# SAM9X75D5M device description
Architecture: ARM926EJ-S; Family: SAM9; Series: SAM9X7
Registers are 32-bit, read-write, reset 0x0 unless marked. A register's access mark holds for its fields unless they carry their own. Offsets are from the block's base; [hi:lo] are bit positions; {n}, {i} and the like mark numbered series; 'fields as' and 'values as' point back to an identical list.

## GMAC (part 2 of 3) — Gigabit Ethernet MAC
Instances: GMAC 0xF802C000
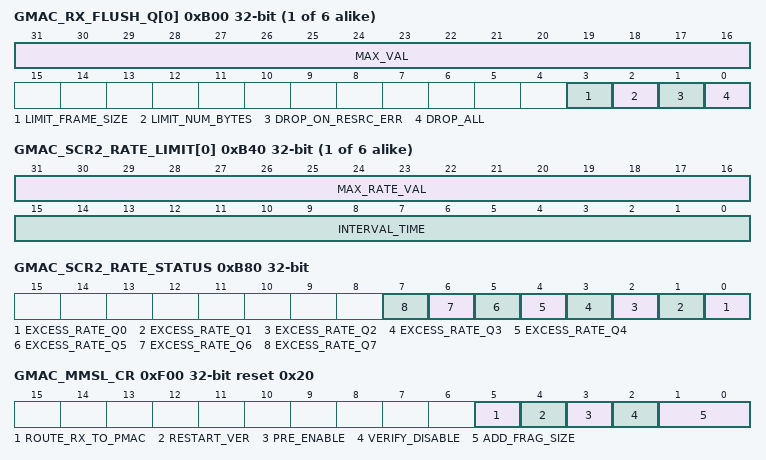
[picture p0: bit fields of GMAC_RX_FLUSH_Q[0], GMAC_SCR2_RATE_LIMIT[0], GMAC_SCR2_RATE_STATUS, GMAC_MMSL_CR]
{0xB00+4i} GMAC_RX_FLUSH_Q[{i}] (i=0..5) — Receive Queue Flush Register (index = 0)
  [31:16] MAX_VAL — Maximum Value for the Received Frame Size or Number of 128-Byte Chunk
  [3] LIMIT_FRAME_SIZE — Maximum Frame-length Received
    0=DISABLED (No effect.); 1=ENABLED (When set, MAX_VAL indicates the maximum frame-length in bytes that may be received. Frames exceeding this length will be dropped. This traffic policing function is relevant to the 802.1Qci standard which specifies stream filtering based on a maximum service data unit (SDU) size.)
  [2] LIMIT_NUM_BYTES — Limitation of the Number of 128-Byte Chunk of Data Stored in the Memory of this Queue
    0=DISABLED (No effect.); 1=ENABLED (Limits the number of 128 byte chunks of data received for this queue and already stored in the memory of the queue awaiting DMA memory writes to the value defined in the field MAX_VAL.)
  [1] DROP_ON_RESRC_ERR — Drop on Resource Error
    0=DISABLED (No effect.); 1=ENABLED (If a free DMA descriptor for this queue cannot be obtained (also referred to as lack of descriptor resource and occurs when the software either cannot free up descriptors quickly enough to meet the receive traffic rate or has deliberately decided not to free any descriptors), all new frames received on this queue will be automatically discarded.)
  [0] DROP_ALL — Drop All Frames
    0=DISABLED (No effect.); 1=ENABLED (Drops all frames of this queue.)
{0xB40+4i} GMAC_SCR2_RATE_LIMIT[{i}] (i=0..5) — Screening 2 Rate Limit Register (index = 0)
  [31:16] MAX_RATE_VAL — Maximum Rate Value for the Interval Time
  [15:0] INTERVAL_TIME — Interval Time for Maximum Rate Checking
0xB80 GMAC_SCR2_RATE_STATUS ro — Screening 2 Rate Status Register
  [all] fields
    0=No excessive rate in screener since the last read of GMAC_SCR2_RATE_STATUS; 1=A screener rate limiting mechanism has been triggered since the last read of GMAC_SCR2_RATE_STATUS
  [n] EXCESS_RATE_Q{n} (n=0..7) — Excessive Screener Rate Queue {n}
0xF00 GMAC_MMSL_CR reset 0x20 — MMSL Control Register
  [5] ROUTE_RX_TO_PMAC — Route Received Frames to Preemptive MAC
    0=Routes all received to express MAC (eMAC); 1=Routes all received frames to preemptive MAC (pMAC)
  [4] RESTART_VER — Restart the Verification Procedure (Write-only)
    0=No effect; 1=Restarts the verification procedure. Writing a one to this bit has no effect if any of the following are true: PRE_ENABLE=0, VERIFY_DISABLE=1 or the verification procedure is already in progress. When preemption is active, ROUTE_RX_TO_PMAC must be set to zero before writing to the RESTART_VER bit. This bit always returns zero when read.
  [3] PRE_ENABLE — Preemption Operation Enable
    0=Disables the preemption operation and verify mpackets will not be responded to or sent. If a preemption is in progress, the current preemption will complete and no more preemption will occur.; 1=Enables the preemption by starting the verification procedure when VERIFY_DISABLE=0. Preemption can occur only once the verification process completes. If VERIFY_DISABLE=1, preemption can occur immediately.
  [2] VERIFY_DISABLE — 802.3br Support Check for the Link Partner
    0=Enables the 802.3br support check for the link partner; 1=Disables the 802.3br support check for the link partner and preemption is enabled as soon as PRE_ENABLE=1
  [1:0] ADD_FRAG_SIZE — PMAC Minimum Number of Bytes before Preemption
    0=64_BYTES (A minimum of 64 bytes can be sent by pMAC before any preemption. The value can be changed only when PRE_ENABLE is cleared); 1=128_BYTES (A minimum of 128 bytes can be sent by pMAC before any preemption. The value can be changed only when PRE_ENABLE is cleared); 2=192_BYTES (A minimum of 192 bytes can be sent by pMAC before any preemption. The value can be changed only when PRE_ENABLE is cleared); 3=256_BYTES (A minimum of 256 bytes can be sent by pMAC before any preemption. The value can be changed only when PRE_ENABLE is cleared)
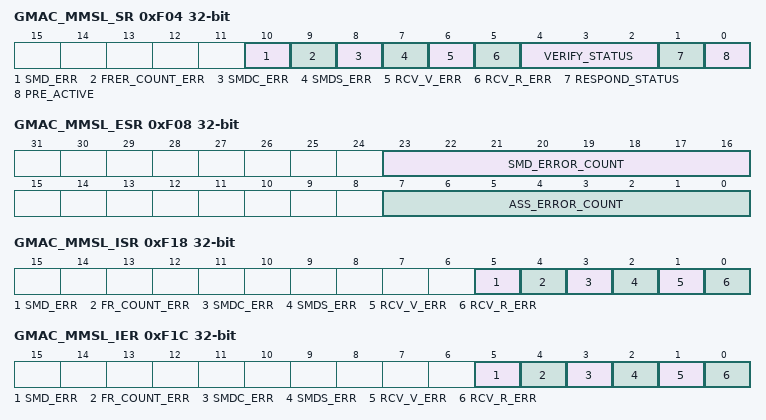
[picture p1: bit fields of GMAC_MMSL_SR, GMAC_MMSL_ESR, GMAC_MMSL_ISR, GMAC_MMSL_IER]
0xF04 GMAC_MMSL_SR ro — MMSL Status Register
  [10] SMD_ERR — Illegal Start Mpacket Delimiter Received (Clear on read)
    0=No error since the last read of GMAC_MMSL_SR; 1=An illegal SMD (different from Express, Verify, Response, Start Preemptible or Continuation Preemptible SMD) has been received since the last read of GMAC_MMSL_SR
  [9] FRER_COUNT_ERR — Frame Counter Error (Clear on read)
    0=No error since the last read of GMAC_MMSL_SR; 1=A frame counter error occurred since the last read of GMAC_MMSL_SR. A frame counter error occurs when the SMD-C received indicates a different frame count than expected (i.e. the fragment belongs to another frame and not to the Start packet already received before this) or when a fragment error happened, which means the field following the SMD-C received was encoding a different fragment count than it was supposed to be.
  [8] SMDC_ERR — SMD-C Received When Waiting an SMD-S (Clear on read)
    0=No error since the last read of GMAC_MMSL_SR; 1=An SMD-C has been received when an SMD-S was expected, since the last read of GMAC_MMSL_SR
  [7] SMDS_ERR — SMD-S Received When Waiting an SMD-C (Clear on read)
    0=No error since the last read of GMAC_MMSL_SR; 1=An SMD-S has been received when an SMD-C was expected, since the last read of GMAC_MMSL_SR
  [6] RCV_V_ERR — Incorrect Verification Mpacket Received (Clear on read)
    0=No error since the last read of GMAC_MMSL_SR; 1=An incorrect verification mPacket has been received since the last read of GMAC_MMSL_SR
  [5] RCV_R_ERR — Incorrect Response Mpacket Received (Clear on read)
    0=No error since the last read of GMAC_MMSL_SR; 1=An incorrect response mPacket has been received since the last read of GMAC_MMSL_SR
  [4:2] VERIFY_STATUS — Verification Status
    0=INIT_VERIFICATION (Initialization); 1=VERIFICATION_IDLE (Idle); 2=SEND_VERIFY (Sending a verify command); 3=WAIT_FOR_RESPONSE (Waiting for a response); 4=VERIFIED; 5=VERIFY_FAIL (Failure during the verify operation)
  [1] RESPOND_STATUS — Response Status
    0=R_IDLE (Idle); 1=SEND_RESPOND (Sending)
  [0] PRE_ACTIVE — Preemption Status
    0=Preemption is inactive; 1=Preemption is active when the verification process is completed or when GMAC_MMSL_CR.VERIFY_DISABLE=1 and GMAC_MMSL_CR.PRE_ACTIVE=1
0xF08 GMAC_MMSL_ESR ro — MMSL Error Statistics Register
  [23:16] SMD_ERROR_COUNT — Number of Rejected Frames or Fragments due to unknown SMD (Clear on read)
  [7:0] ASS_ERROR_COUNT — Number of Frames with Reassembly Errors (Clear on read)
0xF0C GMAC_MMSL_ASS_OK ro — MMSL Frame Re-Assembled OK Register
  [16:0] ASS_OK_COUNT — Number of Correctly Re-Assembled Frames (Clear on read)
0xF10 GMAC_MMSL_RXFRAG_CNT ro — MMSL Received Fragment Counter Register
  [16:0] FRAG_COUNT_RX — Number of Received Fragments (Clear on read)
0xF14 GMAC_MMSL_TXFRAG_CNT ro — MMSL Transmitted Fragment Counter Register
  [16:0] FRAG_COUNT_TX — Number of Transmitted Fragments (Clear on read)
0xF18 GMAC_MMSL_ISR — MMSL Interrupt Status Register
  [5] SMD_ERR — Illegal SMD Received (Clear on read)
    0=No illegal SMD received since the last read of GMAC_MMSL_ISR; 1=Illegal SMD received (different from Express, Verify, Response, Start Preemptible or Continuation Preemptible) since the last read of GMAC_MMSL_ISR
  [4] FR_COUNT_ERR — Illegal SMD Received (Clear on read)
    0=No frame count error detected since the last read of GMAC_MMSL_ISR; 1=The SMD-C received since the last read of GMAC_MMSL_ISR, indicates a different frame count than expected (i.e. the fragment belongs to another frame and not to the Start packet already received before this) or if a Fragment error happened, which means the field following the SMD-C received was encoding a different fragment count than it was supposed to be.
  [3] SMDC_ERR — SMD-C Received When Waiting an SMD-S (Clear on read)
    values as GMAC_MMSL_SR.SMDC_ERR
  [2] SMDS_ERR — SMD-S Received When Waiting an SMD-C (Clear on read)
    values as GMAC_MMSL_SR.SMDS_ERR
  [1] RCV_V_ERR — Incorrect Verification Mpacket Received (Clear on read)
    values as GMAC_MMSL_SR.RCV_V_ERR
  [0] RCV_R_ERR — Incorrect Response Mpacket Received (Clear on read)
    values as GMAC_MMSL_SR.RCV_R_ERR
0xF1C GMAC_MMSL_IER (atomic set of GMAC_MMSL_IMR) — MMSL Interrupt Enable Register
  [5] SMD_ERR — Illegal SMD Received
  [4] FR_COUNT_ERR — Illegal SMD Received
  [3] SMDC_ERR — SMD-C Received When Waiting an SMD-S
  [2] SMDS_ERR — SMD-S Received When Waiting an SMD-C
  [1] RCV_V_ERR — Incorrect Verification Mpacket Received
  [0] RCV_R_ERR — Incorrect Response Mpacket Received
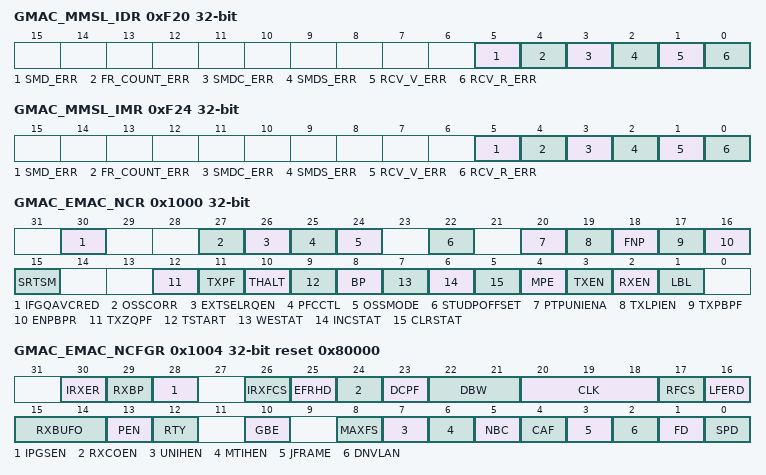
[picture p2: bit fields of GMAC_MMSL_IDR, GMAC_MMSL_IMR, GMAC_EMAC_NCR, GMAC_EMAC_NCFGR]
0xF20 GMAC_MMSL_IDR (atomic clear of GMAC_MMSL_IMR) — MMSL Interrupt Disable Register
  fields as GMAC_MMSL_IER
0xF24 GMAC_MMSL_IMR ro — MMSL Interrupt Mask Register
  fields as GMAC_MMSL_IER
0x1000 GMAC_EMAC_NCR — Express MAC Network Control Register
  [30] IFGQAVCRED — Credit-Based Shaping Algorithm Modification
    0=No modification of the CBS algorithm; 1=Modifies the CBS algorithm so the IFG/IPG associated with a transmit frame counts towards its 802.1Qav credit
  [27] OSSCORR — 1588 One Step Sync Mode Correction Field
    0=Disables updating the correction field of PTP 1588 version 2 sync frames by adding current TSU timer value; 1=Enables updating the correction field of PTP 1588 version 2 sync frames by adding current TSU timer value
  [26] EXTSELRQEN — External Selection of Receive Queue Enable
    0=Disables external selection of receive queue; 1=Enables external selection of receive queue
  [25] PFCCTL — Multiple PFC Pause quantum Enable
    0=Disables multiple PFC pause quantums; 1=Enables multiple PFC pause quantums, one per pause priority
  [24] OSSMODE — One Step Sync Mode
    0=1588 One Step Sync Mode is disabled; 1=1588 One Step Sync Mode is enabled. Replaces timestamp field in the 1588 header for TX Sync Frames with the current TSU timer value.
  [22] STUDPOFFSET — Store UDP Offset
    0=Normal operations; 1=The upper 16 bits of the CRC of every received frame are replaced with the offset from start of frame to the beginning of the UDP or TCP header. The lower 16 bits of the CRC are replaced with zero and reserved for future use. The offset is measured in units of 2 bytes.
  [20] PTPUNIENA — Detection of Unicast PTP Frames Enable
    0=Disables detection of unicast PTP frames; 1=Enables detection of unicast PTP frames
  [19] TXLPIEN — Enable LPI Transmission
  [18] FNP — Flush Next Packet (Write-only)
    0=No effect; 1=Flushes the next packet from the receive memory. This will only have an effect if the DMA is not currently writing a packet already stored in the receive memory to system memory.
  [17] TXPBPF — Transmit PFC Priority-based Pause Frame (Write-only)
    0=No effect; 1=Takes the values stored in the Transmit PFC Pause Register
  [16] ENPBPR — Enable PFC Priority-based Pause Reception
    0=Disables PFC Priority Based Pause Reception capabilities; 1=Enables PFC Priority Based Pause Reception capabilities by enabling the PFC negotiation and recognition of priority-based pause frames
  [15] SRTSM — Store Receive Timestamp to Memory
    0=Normal operation; 1=Causes the CRC of every received frame to be replaced with the value of the nanoseconds field of the 1588 timer that was captured as the receive frame passed the message timestamp point. Note that bit RFCS in register GMAC_NCFGR may not be set to 1 when the timer should be captured.
  [12] TXZQPF — Transmit Zero Quantum Pause Frame (Write-only)
    0=No effect; 1=Generates a pause frame with zero quantum to be transmitted
  [11] TXPF — Transmit Pause Frame (Write-only)
    0=No effect; 1=Generates a pause frame to be transmitted
  [10] THALT — Transmit Halt (Write-only)
    0=No effect; 1=Halts transmission as soon as any ongoing frame transmission ends
  [9] TSTART — Start Transmission (Write-only)
    0=No effect; 1=Starts transmission
  [8] BP — Back Pressure
    0=No effect; 1=When the MAC is set in 10M or 100M Half Duplex mode, forces collisions on all received frames. Ignored in Gigabit Half Duplex mode.
  [7] WESTAT — Write Enable for Statistics Registers
    0=Forces the statistics registers to be in read-only mode for normal operation mode; 1=Makes the statistics registers writable for functional test purposes
  [6] INCSTAT — Increment Statistics Registers (Write-only)
  [5] CLRSTAT — Clear Statistics Registers (Write-only)
    0=No effect; 1=Clears the statistics registers
  [4] MPE — Management Port Enable
    0=Forces GMDIO to high impedance state and MDC low; 1=Enables the management port
  [3] TXEN — Transmit Enable
    0=Stops transmission immediately, the transmit pipeline and control registers will be cleared and the Transmit Queue Pointer Register will reset to point to the start of the transmit descriptor list; 1=Enables the GMAC transmitter to send data
  [2] RXEN — Receive Enable
    0=Stops frame reception immediately and the receive pipeline will be cleared. The Receive Queue Pointer Register is unaffected.; 1=Enables the GMAC to receive data
  [1] LBL — Loop Back Local
    0=Normal operating mode (no loop back); 1=Connects GTX to GRX, GTXEN to GRXDV and forces Full Duplex mode. GRXCK and GTXCK may malfunction as the GMAC is switched into and out of internal loop back. It is important that receive and transmit circuits have already been disabled when making the switch into and out of internal loop back.
0x1004 GMAC_EMAC_NCFGR reset 0x80000 — Express MAC Network Configuration Register
  [30] IRXER — Ignore Receive Error from PHY
    0=0; 1=GRXER has no effect on the GMAC's operation when GRXDV is low. Set this bit when using the RGMII wrapper in Half Duplex mode.
  [29] RXBP — Receive Bad Preamble
    0=Rejects frames with non-standard preamble; 1=Accepts frames with non-standard preamble
  [28] IPGSEN — Inter Packet Gap Stretch Enable
    0=The transmit IPG cannot be increased; 1=The transmit IPG can be increased above 96 bit times depending on the previous frame length using the IPG Stretch Register
  [26] IRXFCS — Ignore RX FCS
    0=Normal operation, frames with FCS/CRC errors are rejected; 1=Frames with FCS/CRC errors are rejected. FCS error statistics are still collected for frames with bad FCS and FCS status is recorded in frame's DMA descriptor.
  [25] EFRHD — Enable Frames Received in Half Duplex
    0=Disables frames to be received in Half Duplex mode while transmitting; 1=Enables frames to be received in Half Duplex mode while transmitting
  [24] RXCOEN — Receive Checksum Offload Enable
    0=Disables the receive checksum engine. Frames with bad IP, TCP or UDP checksums are accepted.; 1=Enables the receive checksum engine. Frames with bad IP, TCP or UDP checksums are discarded.
  [23] DCPF — Disable Copy of Pause Frames
    0=Copies pause frames to the system memory; 1=Prevents valid pause frames being copied to memory. Pause frames are not copied to memory regardless of the state of the Copy All Frames bit, whether a hash match is found or whether a type ID match is identified. If a destination address match is found, the pause frame will be copied to memory. Note that valid pause frames received will still increment pause statistics and pause the transmission of frames as required.
  [22:21] DBW — Always Written to 0
  [20:18] CLK — MDC Clock Division
    0=MCK_8 (MCK divided by 8 (MCK up to 20 MHz)); 1=MCK_16 (MCK divided by 16 (MCK up to 40 MHz)); 2=MCK_32 (MCK divided by 32 (MCK up to 80 MHz)); 3=MCK_48 (MCK divided by 48 (MCK up to 120 MHz)); 4=MCK_64 (MCK divided by 64 (MCK up to 160 MHz)); 5=MCK_96 (MCK divided by 96 (MCK up to 240 MHz))
  [17] RFCS — Remove FCS
    0=Includes the received frame check sequence (last 4 bytes) when writing to memory; 1=Excludes the received frame check sequence (last 4 bytes) when writing to memory. The frame length indicated will be reduced by four bytes in this mode.
  [16] LFERD — Length Field Error Frame Discard
    0=Accepts frames with a measured length shorter than the extracted length field; 1=Discards frames with a measured length shorter than the extracted length field (as indicated by bytes 13 and 14 in a non-VLAN tagged frame). This only applies to frames with a length field less than 0x0600.
  [15:14] RXBUFO — Receive Buffer Offset
  [13] PEN — Pause Enable
    0=Does not pause the transmission when a non-zero 802.3 classic pause frame is received; 1=Pauses transmission when a non-zero 802.3 classic pause frame is received and PFC has not been negotiated
  [12] RTY — Retry Test0
    0=Normal operation; 1=The backoff between collisions will always be one slot time and helps test the too many retries condition. Also used in the pause frame tests to reduce the pause counter's decrement time from 512 bit times, to every GRXCK cycle.
  [10] GBE — Gigabit Mode Enable
    0=Operates in 10/100Mbps mode; 1=Operates in Gigabit mode
  [8] MAXFS — 1536 Maximum Frame Size
    0=Rejects frame sizes above 1518 bytes; 1=Accepts frames up to 1536 bytes in length. Normally the GMAC would reject any frame above 1518 bytes.
  [7] UNIHEN — Unicast Hash Enable
    0=Rejects unicast frames; 1=Accepts unicast frames when the 6-bit hash function of the destination address points to a bit that is set in the Hash Register
  [6] MTIHEN — Multicast Hash Enable
    0=Rejects multicast frames; 1=Accepts multicast frames when the 6-bit hash function of the destination address points to a bit that is set in the Hash Register
  [5] NBC — No Broadcast
    0=Accepts broadcast frames; 1=Rejects frames addressed to the broadcast address of all ones
  [4] CAF — Copy All Frames
    0=Discards invalid frames; 1=Accepts all valid frames
  [3] JFRAME — Jumbo Frame Size
    0=Disables jumbo frames; 1=Enables jumbo frames up to 10240 bytes to be accepted. The default length is 10240 bytes.
  [2] DNVLAN — Discard Non-VLAN FRAMES
    0=Passes all frames to address matching logic; 1=Passes only VLAN tagged frames to the address matching logic
  [1] FD — Full Duplex
    0=Half-duplex mode; 1=The transmit block ignores the state of collision and carrier sense and allows receive while transmitting
  [0] SPD — Speed
    0=MAC operates at 10 Mbps; 1=MAC Operates at 100 Mbps
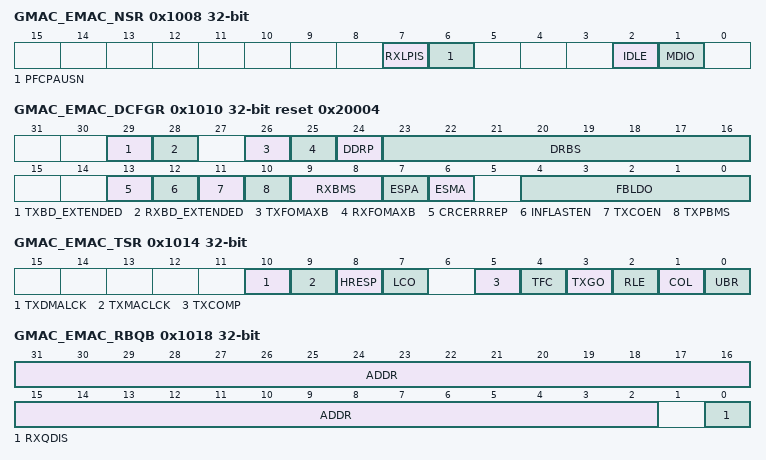
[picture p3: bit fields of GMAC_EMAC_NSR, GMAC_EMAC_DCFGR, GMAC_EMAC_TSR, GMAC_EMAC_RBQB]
0x1008 GMAC_EMAC_NSR ro reset not defined — Express MAC Network Status Register
  [7] RXLPIS — LPI Indication
  [6] PFCPAUSN — PFC Pause Negotiated
  [2] IDLE — PHY Management Logic Idle
  [1] MDIO — MDIO Input Status
0x1010 GMAC_EMAC_DCFGR reset 0x20004 — Express MAC DMA Configuration Register
  [29] TXBD_EXTENDED — Transmit Buffer Descriptor Extended Mode
    0=Disables Transmit Buffer Data Extended mode; 1=Enables Transmit Buffer Data Extended mode
  [28] RXBD_EXTENDED — Receive Buffer Descriptor Extended Mode
    0=Disables Receive Buffer Data Extended mode; 1=Enables Receive Buffer Data Extended mode
  [26] TXFOMAXB — Force Transmit Max Burst Length
  [25] RXFOMAXB — Force Receive Max Burst Length
  [24] DDRP — DMA Discard Receive Packets
  [23:16] DRBS — DMA Receive Buffer Size
    2=128 bytes; 24=1536 bytes (1 x max length frame/buffer); 160=10240 bytes (1 x 10K jumbo frame/buffer)
  [13] CRCERRREP — CRC Errors Report
    0=Bit 16 of the receive buffer descriptor represents the Canonical format indicator (CFI) bit as extracted from the receive frame (if the receive buffer descriptor is pointing to the last data buffer of the receive frame and the received frame was VLAN tagged); 1=Bit 16 of the receive buffer descriptor represents the FCS/CRC error (only if frames with FCS are copied to memory as enabled by bit 26 in the Network Configuration register)
  [12] INFLASTEN — Infinite Size for Last Buffer Enable
  [11] TXCOEN — Transmitter Checksum Generation Offload Enable
  [10] TXPBMS — Transmitter Packet Buffer Memory Size Select
    0=TWO_KB (Do not use top address bit (2 Kbytes).); 1=FOUR_KB (Use full configured addressable space (4 Kbytes).)
  [9:8] RXBMS — Receiver Packet Buffer Memory Size Select
    0=EIGHTH (4/8 Kbyte Memory Size); 1=QUARTER (4/4 Kbytes Memory Size); 2=HALF (4/2 Kbytes Memory Size); 3=FULL (4 Kbytes Memory Size)
  [7] ESPA — Endian Swap Mode Enable for Packet Data Accesses
    0=LITTLE_ENDIAN (Selects Little-endian endianism for system bus transfers.); 1=BIG_ENDIAN (Selects swapped endianism for system bus transfers.)
  [6] ESMA — Endian Swap Mode Enable for Management Descriptor Accesses
    values as ESPA
  [4:0] FBLDO — Fixed Burst Length for DMA Data Operations:
    1=SINGLE (Always use single access on system bus); 4=INCR4 (Attempt to use 4-beat bursts on system bus (Default)); 8=INCR8 (Attempt to use 8-beat bursts on system bus bursts); 16=INCR16 (Attempt to use 16-beat bursts on system bus bursts)
0x1014 GMAC_EMAC_TSR — Express MAC Transmit Status Register
  [10] TXDMALCK — Transmit DMA Lockup (Clear by Writing a 1)
  [9] TXMACLCK — Transmit MAC Lockup (Clear by Writing a 1)
  [8] HRESP — System Bus Response (Clear by Writing a 1)
  [7] LCO — Late Collision Occurred (Clear by Writing a 1)
  [5] TXCOMP — Transmit Complete (Clear by Writing a 1)
  [4] TFC — Transmit Frame Corruption Due to System Bus Error (Clear by Writing a 1)
  [3] TXGO — Transmit Go (Read only)
  [2] RLE — Retry Limit Exceeded (Clear by Writing a 1)
  [1] COL — Collision Occurred (Clear by Writing a 1)
  [0] UBR — Used Bit Read (Clear by Writing a 1)
0x1018 GMAC_EMAC_RBQB — Express MAC Receive Buffer Queue Base Address Register
  [31:2] ADDR — Receive Buffer Queue Base Address
  [0] RXQDIS — Receive Queue Disable
    0=Queue is enabled; 1=Queue is disabled. Used to reduce the number of active queues and should only be changed while receive is not enabled.
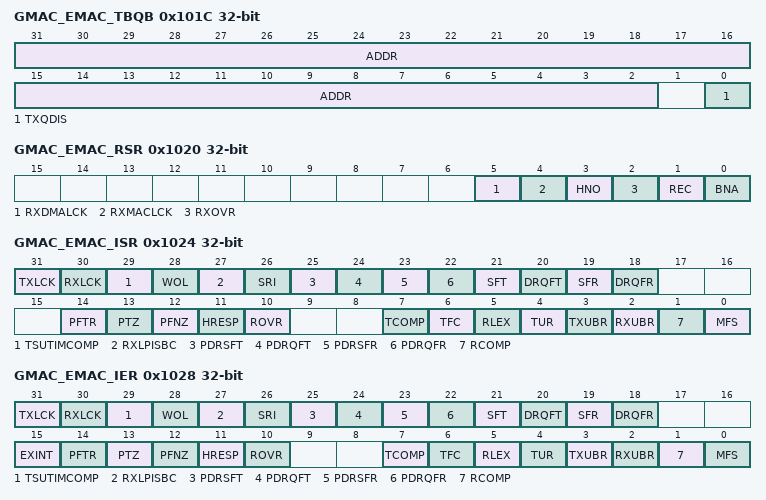
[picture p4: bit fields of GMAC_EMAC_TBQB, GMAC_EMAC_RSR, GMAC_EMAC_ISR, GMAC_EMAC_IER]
0x101C GMAC_EMAC_TBQB — Express MAC Transmit Buffer Queue Base Address Register
  [31:2] ADDR — Transmit Buffer Queue Base Address
  [0] TXQDIS — Transmit Queue Disable
    0=Queue is enabled; 1=Queue is disabled. Used to reduce the number of active queues and should only be changed while transmit is not enabled.
0x1020 GMAC_EMAC_RSR — Express MAC Receive Status Register
  [5] RXDMALCK — Receive DMA Lockup (Clear by Writing a 1)
  [4] RXMACLCK — Receive MAC Lockup (Clear by Writing a 1)
  [3] HNO — System Bus Error (Clear by Writing a 1)
  [2] RXOVR — Receive Overrun (Clear by Writing a 1)
  [1] REC — Frame Received (Clear by Writing a 1)
  [0] BNA — Buffer Not Available (Clear by Writing a 1)
0x1024 GMAC_EMAC_ISR ro — Express MAC Interrupt Status Register
  [31] TXLCK — Transmit Path Locked (Cleared on read)
  [30] RXLCK — Receive Path Locked (Cleared on read)
  [29] TSUTIMCOMP — TSU Timer Comparison (Cleared on read)
  [28] WOL — Wake On LAN (Cleared on read)
  [27] RXLPISBC — Receive LPI indication Status Bit Change (Cleared on read)
  [26] SRI — TSU Seconds Register Increment (Cleared on read)
  [25] PDRSFT — PDelay Response Frame Transmitted (Cleared on read)
  [24] PDRQFT — PDelay Request Frame Transmitted (Cleared on read)
  [23] PDRSFR — PDelay Response Frame Received (Cleared on read)
  [22] PDRQFR — PDelay Request Frame Received (Cleared on read)
  [21] SFT — PTP Sync Frame Transmitted (Cleared on read)
  [20] DRQFT — PTP Delay Request Frame Transmitted (Cleared on read)
  [19] SFR — PTP Sync Frame Received (Cleared on read)
  [18] DRQFR — PTP Delay Request Frame Received (Cleared on read)
  [14] PFTR — Pause Frame Transmitted (Cleared on read)
  [13] PTZ — Pause Time Zero (Cleared on read)
  [12] PFNZ — Pause Frame with Non-zero Pause Quantum Received (Cleared on read)
  [11] HRESP — System Bus Error (Cleared on read)
  [10] ROVR — Receive Overrun (Cleared on read)
  [7] TCOMP — Transmit Complete (Cleared on read)
  [6] TFC — Transmit Frame Corruption Due to System Bus Error (Cleared on read)
  [5] RLEX — Retry Limit Exceeded or Late Collision (Cleared on read)
  [4] TUR — Transmit Underrun (Cleared on read)
  [3] TXUBR — TX Used Bit Read (Cleared on read)
  [2] RXUBR — RX Used Bit Read (Cleared on read)
  [1] RCOMP — Receive Complete (Cleared on read)
  [0] MFS — Management Frame Sent (Cleared on read)
0x1028 GMAC_EMAC_IER wo reset not defined (atomic set of GMAC_EMAC_IMR) — Express MAC Interrupt Enable Register
  [31] TXLCK — Transmit Path Lockup Detected
  [30] RXLCK — Receive Path Lockup Detected
  [29] TSUTIMCOMP — TSU Timer Comparison
  [28] WOL — Wake On LAN
  [27] RXLPISBC — Enable RX LPI Indication
  [26] SRI — TSU Seconds Register Increment
  [25] PDRSFT — PDelay Response Frame Transmitted
  [24] PDRQFT — PDelay Request Frame Transmitted
  [23] PDRSFR — PDelay Response Frame Received
  [22] PDRQFR — PDelay Request Frame Received
  [21] SFT — PTP Sync Frame Transmitted
  [20] DRQFT — PTP Delay Request Frame Transmitted
  [19] SFR — PTP Sync Frame Received
  [18] DRQFR — PTP Delay Request Frame Received
  [15] EXINT — External Interrupt
  [14] PFTR — Pause Frame Transmitted
  [13] PTZ — Pause Time Zero
  [12] PFNZ — Pause Frame with Non-zero Pause Quantum Received
  [11] HRESP — System Bus Error
  [10] ROVR — Receive Overrun
  [7] TCOMP — Transmit Complete
  [6] TFC — Transmit Frame Corruption Due to System Bus Error
  [5] RLEX — Retry Limit Exceeded or Late Collision
  [4] TUR — Transmit Underrun
  [3] TXUBR — TX Used Bit Read
  [2] RXUBR — RX Used Bit Read
  [1] RCOMP — Receive Complete
  [0] MFS — Management Frame Sent
